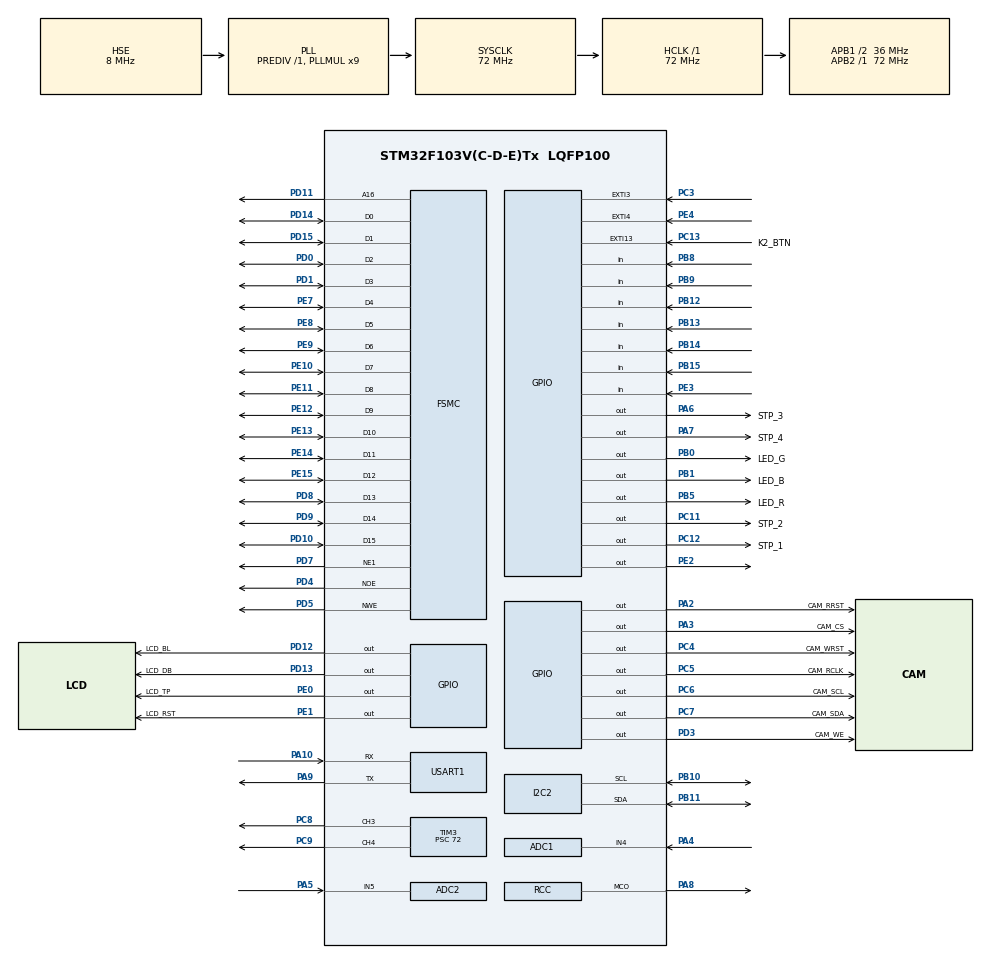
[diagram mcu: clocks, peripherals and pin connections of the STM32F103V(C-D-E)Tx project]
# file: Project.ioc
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ADC1.Channel-1\#ChannelRegularConversion=ADC_CHANNEL_4
ADC1.ContinuousConvMode=ENABLE
ADC1.NbrOfConversionFlag=1
ADC1.Rank-1\#ChannelRegularConversion=1
ADC1.SamplingTime-1\#ChannelRegularConversion=ADC_SAMPLETIME_1CYCLE_5
ADC1.master=1
ADC2.Channel-0\#ChannelRegularConversion=ADC_CHANNEL_5
ADC2.ContinuousConvMode=ENABLE
ADC2.NbrOfConversion=1
ADC2.NbrOfConversionFlag=1
ADC2.Rank-0\#ChannelRegularConversion=1
ADC2.SamplingTime-0\#ChannelRegularConversion=ADC_SAMPLETIME_1CYCLE_5
Mcu.Family=STM32F1
Mcu.Name=STM32F103V(C-D-E)Tx
Mcu.Package=LQFP100
NVIC.EXTI15_10_IRQn=true\:0\:0\:false\:false\:true\:true\:true\:true
NVIC.EXTI3_IRQn=true\:0\:0\:false\:false\:true\:true\:true\:true
NVIC.EXTI4_IRQn=true\:0\:0\:false\:false\:true\:true\:true\:true
NVIC.PriorityGroup=NVIC_PRIORITYGROUP_4
OSC_IN.Mode=HSE-External-Oscillator
OSC_IN.Signal=RCC_OSC_IN
OSC_OUT.Mode=HSE-External-Oscillator
OSC_OUT.Signal=RCC_OSC_OUT
PA10.Mode=Asynchronous
PA10.Signal=USART1_RX
PA13.Mode=Serial_Wire
PA13.Signal=SYS_JTMS-SWDIO
PA14.Mode=Serial_Wire
PA14.Signal=SYS_JTCK-SWCLK
PA2.GPIO_Label=CAM_RRST
PA2.GPIO_Speed=GPIO_SPEED_FREQ_HIGH
PA2.PinState=GPIO_PIN_RESET
PA2.Signal=GPIO_Output
PA3.GPIO_Label=CAM_CS
PA3.GPIO_Speed=GPIO_SPEED_FREQ_HIGH
PA3.Signal=GPIO_Output
PA4.Signal=ADCx_IN4
PA5.Signal=ADCx_IN5
PA6.GPIO_Label=STP_3
PA6.GPIO_Speed=GPIO_SPEED_FREQ_HIGH
PA6.PinState=GPIO_PIN_SET
PA6.Signal=GPIO_Output
PA7.GPIO_Label=STP_4
PA7.GPIO_Speed=GPIO_SPEED_FREQ_HIGH
PA7.PinState=GPIO_PIN_SET
PA7.Signal=GPIO_Output
PA8.Mode=Clock-out
PA8.Signal=RCC_MCO
PA9.Mode=Asynchronous
PA9.Signal=USART1_TX
PB0.GPIO_Label=LED_G
PB0.GPIO_Speed=GPIO_SPEED_FREQ_HIGH
PB0.PinState=GPIO_PIN_SET
PB0.Signal=GPIO_Output
PB1.GPIO_Label=LED_B
PB1.GPIO_Speed=GPIO_SPEED_FREQ_HIGH
PB1.PinState=GPIO_PIN_SET
PB1.Signal=GPIO_Output
PB10.Mode=I2C
PB10.Signal=I2C2_SCL
PB11.Mode=I2C
PB11.Signal=I2C2_SDA
PB12.Signal=GPIO_Input
PB13.Signal=GPIO_Input
PB14.Signal=GPIO_Input
PB15.Signal=GPIO_Input
PB5.GPIO_Label=LED_R
PB5.GPIO_Speed=GPIO_SPEED_FREQ_HIGH
PB5.PinState=GPIO_PIN_SET
PB5.Signal=GPIO_Output
PB8.Signal=GPIO_Input
PB9.Signal=GPIO_Input
PC11.GPIO_Label=STP_2
PC11.GPIO_Speed=GPIO_SPEED_FREQ_HIGH
PC11.PinState=GPIO_PIN_SET
PC11.Signal=GPIO_Output
PC12.GPIO_Label=STP_1
PC12.GPIO_Speed=GPIO_SPEED_FREQ_HIGH
PC12.PinState=GPIO_PIN_SET
PC12.Signal=GPIO_Output
PC13-TAMPER-RTC.GPIO_Label=K2_BTN
PC13-TAMPER-RTC.GPIO_ModeDefaultEXTI=GPIO_MODE_IT_RISING
PC13-TAMPER-RTC.Signal=GPXTI13
PC14-OSC32_IN.Mode=LSE-External-Oscillator
PC14-OSC32_IN.Signal=RCC_OSC32_IN
PC15-OSC32_OUT.Mode=LSE-External-Oscillator
PC15-OSC32_OUT.Signal=RCC_OSC32_OUT
PC3.GPIO_ModeDefaultEXTI=GPIO_MODE_IT_FALLING
PC3.Signal=GPXTI3
PC4.GPIO_Label=CAM_WRST
PC4.GPIO_Speed=GPIO_SPEED_FREQ_HIGH
PC4.Signal=GPIO_Output
PC5.GPIO_Label=CAM_RCLK
PC5.GPIO_Speed=GPIO_SPEED_FREQ_HIGH
PC5.Signal=GPIO_Output
PC6.GPIO_Label=CAM_SCL
PC6.GPIO_Speed=GPIO_SPEED_FREQ_HIGH
PC6.Signal=GPIO_Output
PC7.GPIO_Label=CAM_SDA
PC7.GPIO_ModeDefaultOutputPP=GPIO_MODE_OUTPUT_OD
PC7.GPIO_PuPd=GPIO_NOPULL
PC7.GPIO_Speed=GPIO_SPEED_FREQ_HIGH
PC7.Signal=GPIO_Output
PC8.GPIO_Speed=GPIO_SPEED_FREQ_HIGH
PC8.Signal=S_TIM3_CH3
PC9.GPIO_Speed=GPIO_SPEED_FREQ_HIGH
PC9.Signal=S_TIM3_CH4
PD0.Mode=16b-d1
PD0.Signal=FSMC_D2
PD1.Mode=16b-d1
PD1.Signal=FSMC_D3
PD10.Mode=16b-d1
PD10.Signal=FSMC_D15
PD11.Mode=A16_1
PD11.Signal=FSMC_A16
PD12.GPIO_Label=LCD_BL
PD12.GPIO_Speed=GPIO_SPEED_FREQ_HIGH
PD12.Signal=GPIO_Output
PD13.GPIO_Label=LCD_DB
PD13.GPIO_Speed=GPIO_SPEED_FREQ_HIGH
PD13.Signal=GPIO_Output
PD14.Mode=16b-d1
PD14.Signal=FSMC_D0
PD15.Mode=16b-d1
PD15.Signal=FSMC_D1
PD3.GPIO_Label=CAM_WE
PD3.GPIO_Speed=GPIO_SPEED_FREQ_HIGH
PD3.Signal=GPIO_Output
PD4.Mode=Lcd1
PD4.Signal=FSMC_NOE
PD5.Mode=Lcd1
PD5.Signal=FSMC_NWE
PD7.Mode=NorPsramChipSelect1_1
PD7.Signal=FSMC_NE1
PD8.Mode=16b-d1
PD8.Signal=FSMC_D13
PD9.Mode=16b-d1
PD9.Signal=FSMC_D14
PE0.GPIO_Label=LCD_TP
PE0.GPIO_Speed=GPIO_SPEED_FREQ_HIGH
PE0.Signal=GPIO_Output
PE1.GPIO_Label=LCD_RST
PE1.GPIO_Speed=GPIO_SPEED_FREQ_HIGH
PE1.Signal=GPIO_Output
PE10.Mode=16b-d1
PE10.Signal=FSMC_D7
PE11.Mode=16b-d1
PE11.Signal=FSMC_D8
PE12.Mode=16b-d1
PE12.Signal=FSMC_D9
PE13.Mode=16b-d1
PE13.Signal=FSMC_D10
PE14.Mode=16b-d1
PE14.Signal=FSMC_D11
PE15.Mode=16b-d1
PE15.Signal=FSMC_D12
PE2.GPIO_Speed=GPIO_SPEED_FREQ_HIGH
PE2.Signal=GPIO_Output
PE3.GPIO_PuPd=GPIO_PULLUP
PE3.Signal=GPIO_Input
PE4.GPIO_ModeDefaultEXTI=GPIO_MODE_IT_FALLING
PE4.Signal=GPXTI4
PE7.Mode=16b-d1
PE7.Signal=FSMC_D4
PE8.Mode=16b-d1
PE8.Signal=FSMC_D5
PE9.Mode=16b-d1
PE9.Signal=FSMC_D6
ProjectManager.HeapSize=0x200
ProjectManager.StackSize=0x400
ProjectManager.TargetToolchain=STM32CubeIDE
RCC.ADCPresc=RCC_ADCPCLK2_DIV6
RCC.AHBFreq_Value=72000000
RCC.APB1CLKDivider=RCC_HCLK_DIV2
RCC.APB1Freq_Value=36000000
RCC.APB1TimFreq_Value=72000000
RCC.APB2Freq_Value=72000000
RCC.APB2TimFreq_Value=72000000
RCC.HCLKFreq_Value=72000000
RCC.PLLMUL=RCC_PLL_MUL9
RCC.PLLSourceVirtual=RCC_PLLSOURCE_HSE
RCC.RCC_MCOSource=RCC_MCO1SOURCE_PLLCLK
RCC.SYSCLKFreq_VALUE=72000000
RCC.SYSCLKSource=RCC_SYSCLKSOURCE_PLLCLK
RCC.USBFreq_Value=72000000
SH.ADCx_IN4.0=ADC1_IN4,IN4
SH.ADCx_IN5.0=ADC2_IN5,IN5
SH.S_TIM3_CH3.0=TIM3_CH3,PWM Generation3 CH3
SH.S_TIM3_CH4.0=TIM3_CH4,PWM Generation4 CH4
TIM1.Period=0xffff-1
TIM1.Prescaler=72-1
TIM3.Channel-PWM\ Generation3\ CH3=TIM_CHANNEL_3
TIM3.Channel-PWM\ Generation4\ CH4=TIM_CHANNEL_4
TIM3.Period=20000-1
TIM3.Prescaler=72
TIM3.Pulse-PWM\ Generation3\ CH3=2000
TIM3.Pulse-PWM\ Generation4\ CH4=2000
USART1.VirtualMode=VM_ASYNC
VP_TIM1_VS_ClockSourceINT.Mode=Internal
board=custom

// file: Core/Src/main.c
/* USER CODE BEGIN Header */
/**
 ******************************************************************************
 * @file           : main.c
 * @brief          : Main program body
 ******************************************************************************
 * @attention
 *
 * Copyright (c) 2024 STMicroelectronics.
 * All rights reserved.
 *
 * This software is licensed under terms that can be found in the LICENSE file
 * in the root directory of this software component.
 * If no LICENSE file comes with this software, it is provided AS-IS.
 *
 ******************************************************************************
 */
/* USER CODE END Header */
#include "main.h"

 ADC_HandleTypeDef hadc1;
ADC_HandleTypeDef hadc2;

I2C_HandleTypeDef hi2c2;

TIM_HandleTypeDef htim1;
TIM_HandleTypeDef htim3;

UART_HandleTypeDef huart1;

SRAM_HandleTypeDef hsram1;

/* USER CODE BEGIN PV */
volatile uint8_t isScreenTouched = 0;
/* USER CODE END PV */

void SystemClock_Config(void);
static void MX_GPIO_Init(void);
static void MX_FSMC_Init(void);
static void MX_I2C2_Init(void);
static void MX_USART1_UART_Init(void);
static void MX_TIM1_Init(void);
static void MX_TIM3_Init(void);
static void MX_ADC1_Init(void);
static void MX_ADC2_Init(void);

int main(void)
{

  /* MCU Configuration--------------------------------------------------------*/

  /* Reset of all peripherals, Initializes the Flash interface and the Systick. */
  HAL_Init();

  /* Configure the system clock */
  SystemClock_Config();

  /* Initialize all configured peripherals */
  MX_GPIO_Init();
  MX_FSMC_Init();
  MX_I2C2_Init();
  MX_USART1_UART_Init();
  MX_TIM1_Init();
  MX_TIM3_Init();
  MX_ADC1_Init();
  MX_ADC2_Init();

  /* Infinite loop */
  /* USER CODE BEGIN WHILE */

  // this is the entry point to my C++ source code files.
  // the STM32CubeIDE does not seem to be able to generate and update
  // C++ main.cpp files for some reason.
  // the work around is to have another C++ source file that contains the
  // real entry point which this generated main.c source file will call after
  // completing initialization.
  extern int mymain(void);

  //  while (1)  comment out the while() because the main loop is in mymain() in mymain.cpp

  // this is the entry point to my C++ source code files.
  // the STM32CubeIDE does not seem to be able to generate and update
  // C++ main.cpp files for some reason.
  // the work around is to have another C++ source file that contains the
  // real entry point which this generated main.c source file will call after
  // completing initialization.
  extern int mymain(void);

  //  while (1)  comment out the while() because the main loop is in mymain() in mymain.cpp
  {
    /* USER CODE END WHILE */

    /* USER CODE BEGIN 3 */
  }

  // the main entry point in the C++ source after initializing
  // the runtime environment.
  return mymain();

  // the main entry point in the C++ source after initializing
  // the runtime environment.
  return mymain();
  /* USER CODE END 3 */
}

void SystemClock_Config(void)
{
  RCC_OscInitTypeDef RCC_OscInitStruct = {0};
  RCC_ClkInitTypeDef RCC_ClkInitStruct = {0};
  RCC_PeriphCLKInitTypeDef PeriphClkInit = {0};

  /** Initializes the RCC Oscillators according to the specified parameters
  * in the RCC_OscInitTypeDef structure.
  */
  RCC_OscInitStruct.OscillatorType = RCC_OSCILLATORTYPE_HSE;
  RCC_OscInitStruct.HSEState = RCC_HSE_ON;
  RCC_OscInitStruct.HSEPredivValue = RCC_HSE_PREDIV_DIV1;
  RCC_OscInitStruct.HSIState = RCC_HSI_ON;
  RCC_OscInitStruct.PLL.PLLState = RCC_PLL_ON;
  RCC_OscInitStruct.PLL.PLLSource = RCC_PLLSOURCE_HSE;
  RCC_OscInitStruct.PLL.PLLMUL = RCC_PLL_MUL9;
  if (HAL_RCC_OscConfig(&RCC_OscInitStruct) != HAL_OK)
  {
    Error_Handler();
  }

  /** Initializes the CPU, AHB and APB buses clocks
  */
  RCC_ClkInitStruct.ClockType = RCC_CLOCKTYPE_HCLK|RCC_CLOCKTYPE_SYSCLK
                              |RCC_CLOCKTYPE_PCLK1|RCC_CLOCKTYPE_PCLK2;
  RCC_ClkInitStruct.SYSCLKSource = RCC_SYSCLKSOURCE_PLLCLK;
  RCC_ClkInitStruct.AHBCLKDivider = RCC_SYSCLK_DIV1;
  RCC_ClkInitStruct.APB1CLKDivider = RCC_HCLK_DIV2;
  RCC_ClkInitStruct.APB2CLKDivider = RCC_HCLK_DIV1;

  if (HAL_RCC_ClockConfig(&RCC_ClkInitStruct, FLASH_LATENCY_2) != HAL_OK)
  {
    Error_Handler();
  }
  PeriphClkInit.PeriphClockSelection = RCC_PERIPHCLK_ADC;
  PeriphClkInit.AdcClockSelection = RCC_ADCPCLK2_DIV6;
  if (HAL_RCCEx_PeriphCLKConfig(&PeriphClkInit) != HAL_OK)
  {
    Error_Handler();
  }
  HAL_RCC_MCOConfig(RCC_MCO, RCC_MCO1SOURCE_PLLCLK, RCC_MCODIV_1);
}

static void MX_ADC1_Init(void)
{

  ADC_ChannelConfTypeDef sConfig = {0};

  /** Common config
  */
  hadc1.Instance = ADC1;
  hadc1.Init.ScanConvMode = ADC_SCAN_DISABLE;
  hadc1.Init.ContinuousConvMode = ENABLE;
  hadc1.Init.DiscontinuousConvMode = DISABLE;
  hadc1.Init.ExternalTrigConv = ADC_SOFTWARE_START;
  hadc1.Init.DataAlign = ADC_DATAALIGN_RIGHT;
  hadc1.Init.NbrOfConversion = 1;
  if (HAL_ADC_Init(&hadc1) != HAL_OK)
  {
    Error_Handler();
  }

  /** Configure Regular Channel
  */
  sConfig.Channel = ADC_CHANNEL_4;
  sConfig.Rank = ADC_REGULAR_RANK_1;
  sConfig.SamplingTime = ADC_SAMPLETIME_1CYCLE_5;
  if (HAL_ADC_ConfigChannel(&hadc1, &sConfig) != HAL_OK)
  {
    Error_Handler();
  }

}

static void MX_ADC2_Init(void)
{

  ADC_ChannelConfTypeDef sConfig = {0};

  /** Common config
  */
  hadc2.Instance = ADC2;
  hadc2.Init.ScanConvMode = ADC_SCAN_DISABLE;
  hadc2.Init.ContinuousConvMode = ENABLE;
  hadc2.Init.DiscontinuousConvMode = DISABLE;
  hadc2.Init.ExternalTrigConv = ADC_SOFTWARE_START;
  hadc2.Init.DataAlign = ADC_DATAALIGN_RIGHT;
  hadc2.Init.NbrOfConversion = 1;
  if (HAL_ADC_Init(&hadc2) != HAL_OK)
  {
    Error_Handler();
  }

  /** Configure Regular Channel
  */
  sConfig.Channel = ADC_CHANNEL_5;
  sConfig.Rank = ADC_REGULAR_RANK_1;
  sConfig.SamplingTime = ADC_SAMPLETIME_1CYCLE_5;
  if (HAL_ADC_ConfigChannel(&hadc2, &sConfig) != HAL_OK)
  {
    Error_Handler();
  }

}

static void MX_I2C2_Init(void)
{

  hi2c2.Instance = I2C2;
  hi2c2.Init.ClockSpeed = 100000;
  hi2c2.Init.DutyCycle = I2C_DUTYCYCLE_2;
  hi2c2.Init.OwnAddress1 = 0;
  hi2c2.Init.AddressingMode = I2C_ADDRESSINGMODE_7BIT;
  hi2c2.Init.DualAddressMode = I2C_DUALADDRESS_DISABLE;
  hi2c2.Init.OwnAddress2 = 0;
  hi2c2.Init.GeneralCallMode = I2C_GENERALCALL_DISABLE;
  hi2c2.Init.NoStretchMode = I2C_NOSTRETCH_DISABLE;
  if (HAL_I2C_Init(&hi2c2) != HAL_OK)
  {
    Error_Handler();
  }

}

static void MX_TIM1_Init(void)
{

  TIM_ClockConfigTypeDef sClockSourceConfig = {0};
  TIM_MasterConfigTypeDef sMasterConfig = {0};

  htim1.Instance = TIM1;
  htim1.Init.Prescaler = 72-1;
  htim1.Init.CounterMode = TIM_COUNTERMODE_UP;
  htim1.Init.Period = 0xffff-1;
  htim1.Init.ClockDivision = TIM_CLOCKDIVISION_DIV1;
  htim1.Init.RepetitionCounter = 0;
  htim1.Init.AutoReloadPreload = TIM_AUTORELOAD_PRELOAD_DISABLE;
  if (HAL_TIM_Base_Init(&htim1) != HAL_OK)
  {
    Error_Handler();
  }
  sClockSourceConfig.ClockSource = TIM_CLOCKSOURCE_INTERNAL;
  if (HAL_TIM_ConfigClockSource(&htim1, &sClockSourceConfig) != HAL_OK)
  {
    Error_Handler();
  }
  sMasterConfig.MasterOutputTrigger = TIM_TRGO_RESET;
  sMasterConfig.MasterSlaveMode = TIM_MASTERSLAVEMODE_DISABLE;
  if (HAL_TIMEx_MasterConfigSynchronization(&htim1, &sMasterConfig) != HAL_OK)
  {
    Error_Handler();
  }

}

static void MX_TIM3_Init(void)
{

  TIM_MasterConfigTypeDef sMasterConfig = {0};
  TIM_OC_InitTypeDef sConfigOC = {0};

  htim3.Instance = TIM3;
  htim3.Init.Prescaler = 72;
  htim3.Init.CounterMode = TIM_COUNTERMODE_UP;
  htim3.Init.Period = 20000-1;
  htim3.Init.ClockDivision = TIM_CLOCKDIVISION_DIV1;
  htim3.Init.AutoReloadPreload = TIM_AUTORELOAD_PRELOAD_DISABLE;
  if (HAL_TIM_PWM_Init(&htim3) != HAL_OK)
  {
    Error_Handler();
  }
  sMasterConfig.MasterOutputTrigger = TIM_TRGO_RESET;
  sMasterConfig.MasterSlaveMode = TIM_MASTERSLAVEMODE_DISABLE;
  if (HAL_TIMEx_MasterConfigSynchronization(&htim3, &sMasterConfig) != HAL_OK)
  {
    Error_Handler();
  }
  sConfigOC.OCMode = TIM_OCMODE_PWM1;
  sConfigOC.Pulse = 2000;
  sConfigOC.OCPolarity = TIM_OCPOLARITY_HIGH;
  sConfigOC.OCFastMode = TIM_OCFAST_DISABLE;
  if (HAL_TIM_PWM_ConfigChannel(&htim3, &sConfigOC, TIM_CHANNEL_3) != HAL_OK)
  {
    Error_Handler();
  }
  if (HAL_TIM_PWM_ConfigChannel(&htim3, &sConfigOC, TIM_CHANNEL_4) != HAL_OK)
  {
    Error_Handler();
  }
  HAL_TIM_MspPostInit(&htim3);

}

static void MX_USART1_UART_Init(void)
{

  huart1.Instance = USART1;
  huart1.Init.BaudRate = 115200;
  huart1.Init.WordLength = UART_WORDLENGTH_8B;
  huart1.Init.StopBits = UART_STOPBITS_1;
  huart1.Init.Parity = UART_PARITY_NONE;
  huart1.Init.Mode = UART_MODE_TX_RX;
  huart1.Init.HwFlowCtl = UART_HWCONTROL_NONE;
  huart1.Init.OverSampling = UART_OVERSAMPLING_16;
  if (HAL_UART_Init(&huart1) != HAL_OK)
  {
    Error_Handler();
  }

}

static void MX_GPIO_Init(void)
{
  GPIO_InitTypeDef GPIO_InitStruct = {0};

  /* GPIO Ports Clock Enable */
  __HAL_RCC_GPIOE_CLK_ENABLE();
  __HAL_RCC_GPIOC_CLK_ENABLE();
  __HAL_RCC_GPIOA_CLK_ENABLE();
  __HAL_RCC_GPIOB_CLK_ENABLE();
  __HAL_RCC_GPIOD_CLK_ENABLE();

  /*Configure GPIO pin Output Level */
  HAL_GPIO_WritePin(GPIOE, GPIO_PIN_2|LCD_TP_Pin|LCD_RST_Pin, GPIO_PIN_RESET);

  /*Configure GPIO pin Output Level */
  HAL_GPIO_WritePin(GPIOA, CAM_RRST_Pin|CAM_CS_Pin, GPIO_PIN_RESET);

  /*Configure GPIO pin Output Level */
  HAL_GPIO_WritePin(GPIOA, STP_3_Pin|STP_4_Pin, GPIO_PIN_SET);

  /*Configure GPIO pin Output Level */
  HAL_GPIO_WritePin(GPIOC, CAM_WRST_Pin|CAM_RCLK_Pin|CAM_SCL_Pin|CAM_SDA_Pin, GPIO_PIN_RESET);

  /*Configure GPIO pin Output Level */
  HAL_GPIO_WritePin(GPIOB, LED_G_Pin|LED_B_Pin|LED_R_Pin, GPIO_PIN_SET);

  /*Configure GPIO pin Output Level */
  HAL_GPIO_WritePin(GPIOD, LCD_BL_Pin|LCD_DB_Pin|CAM_WE_Pin, GPIO_PIN_RESET);

  /*Configure GPIO pin Output Level */
  HAL_GPIO_WritePin(GPIOC, STP_2_Pin|STP_1_Pin, GPIO_PIN_SET);

  /*Configure GPIO pins : PE2 LCD_TP_Pin LCD_RST_Pin */
  GPIO_InitStruct.Pin = GPIO_PIN_2|LCD_TP_Pin|LCD_RST_Pin;
  GPIO_InitStruct.Mode = GPIO_MODE_OUTPUT_PP;
  GPIO_InitStruct.Pull = GPIO_NOPULL;
  GPIO_InitStruct.Speed = GPIO_SPEED_FREQ_HIGH;
  HAL_GPIO_Init(GPIOE, &GPIO_InitStruct);

  /*Configure GPIO pin : PE3 */
  GPIO_InitStruct.Pin = GPIO_PIN_3;
  GPIO_InitStruct.Mode = GPIO_MODE_INPUT;
  GPIO_InitStruct.Pull = GPIO_PULLUP;
  HAL_GPIO_Init(GPIOE, &GPIO_InitStruct);

  /*Configure GPIO pin : PE4 */
  GPIO_InitStruct.Pin = GPIO_PIN_4;
  GPIO_InitStruct.Mode = GPIO_MODE_IT_FALLING;
  GPIO_InitStruct.Pull = GPIO_NOPULL;
  HAL_GPIO_Init(GPIOE, &GPIO_InitStruct);

  /*Configure GPIO pin : K2_BTN_Pin */
  GPIO_InitStruct.Pin = K2_BTN_Pin;
  GPIO_InitStruct.Mode = GPIO_MODE_IT_RISING;
  GPIO_InitStruct.Pull = GPIO_NOPULL;
  HAL_GPIO_Init(K2_BTN_GPIO_Port, &GPIO_InitStruct);

  /*Configure GPIO pin : PC3 */
  GPIO_InitStruct.Pin = GPIO_PIN_3;
  GPIO_InitStruct.Mode = GPIO_MODE_IT_FALLING;
  GPIO_InitStruct.Pull = GPIO_NOPULL;
  HAL_GPIO_Init(GPIOC, &GPIO_InitStruct);

  /*Configure GPIO pins : CAM_RRST_Pin CAM_CS_Pin STP_3_Pin STP_4_Pin */
  GPIO_InitStruct.Pin = CAM_RRST_Pin|CAM_CS_Pin|STP_3_Pin|STP_4_Pin;
  GPIO_InitStruct.Mode = GPIO_MODE_OUTPUT_PP;
  GPIO_InitStruct.Pull = GPIO_NOPULL;
  GPIO_InitStruct.Speed = GPIO_SPEED_FREQ_HIGH;
  HAL_GPIO_Init(GPIOA, &GPIO_InitStruct);

  /*Configure GPIO pins : CAM_WRST_Pin CAM_RCLK_Pin CAM_SCL_Pin STP_2_Pin
                           STP_1_Pin */
  GPIO_InitStruct.Pin = CAM_WRST_Pin|CAM_RCLK_Pin|CAM_SCL_Pin|STP_2_Pin
                          |STP_1_Pin;
  GPIO_InitStruct.Mode = GPIO_MODE_OUTPUT_PP;
  GPIO_InitStruct.Pull = GPIO_NOPULL;
  GPIO_InitStruct.Speed = GPIO_SPEED_FREQ_HIGH;
  HAL_GPIO_Init(GPIOC, &GPIO_InitStruct);

  /*Configure GPIO pins : LED_G_Pin LED_B_Pin LED_R_Pin */
  GPIO_InitStruct.Pin = LED_G_Pin|LED_B_Pin|LED_R_Pin;
  GPIO_InitStruct.Mode = GPIO_MODE_OUTPUT_PP;
  GPIO_InitStruct.Pull = GPIO_NOPULL;
  GPIO_InitStruct.Speed = GPIO_SPEED_FREQ_HIGH;
  HAL_GPIO_Init(GPIOB, &GPIO_InitStruct);

  /*Configure GPIO pins : PB12 PB13 PB14 PB15
                           PB8 PB9 */
  GPIO_InitStruct.Pin = GPIO_PIN_12|GPIO_PIN_13|GPIO_PIN_14|GPIO_PIN_15
                          |GPIO_PIN_8|GPIO_PIN_9;
  GPIO_InitStruct.Mode = GPIO_MODE_INPUT;
  GPIO_InitStruct.Pull = GPIO_NOPULL;
  HAL_GPIO_Init(GPIOB, &GPIO_InitStruct);

  /*Configure GPIO pins : LCD_BL_Pin LCD_DB_Pin CAM_WE_Pin */
  GPIO_InitStruct.Pin = LCD_BL_Pin|LCD_DB_Pin|CAM_WE_Pin;
  GPIO_InitStruct.Mode = GPIO_MODE_OUTPUT_PP;
  GPIO_InitStruct.Pull = GPIO_NOPULL;
  GPIO_InitStruct.Speed = GPIO_SPEED_FREQ_HIGH;
  HAL_GPIO_Init(GPIOD, &GPIO_InitStruct);

  /*Configure GPIO pin : CAM_SDA_Pin */
  GPIO_InitStruct.Pin = CAM_SDA_Pin;
  GPIO_InitStruct.Mode = GPIO_MODE_OUTPUT_OD;
  GPIO_InitStruct.Pull = GPIO_NOPULL;
  GPIO_InitStruct.Speed = GPIO_SPEED_FREQ_HIGH;
  HAL_GPIO_Init(CAM_SDA_GPIO_Port, &GPIO_InitStruct);

  /*Configure GPIO pin : PA8 */
  GPIO_InitStruct.Pin = GPIO_PIN_8;
  GPIO_InitStruct.Mode = GPIO_MODE_AF_PP;
  GPIO_InitStruct.Speed = GPIO_SPEED_FREQ_LOW;
  HAL_GPIO_Init(GPIOA, &GPIO_InitStruct);

  /* EXTI interrupt init*/
  HAL_NVIC_SetPriority(EXTI3_IRQn, 0, 0);
  HAL_NVIC_EnableIRQ(EXTI3_IRQn);

  HAL_NVIC_SetPriority(EXTI4_IRQn, 0, 0);
  HAL_NVIC_EnableIRQ(EXTI4_IRQn);

  HAL_NVIC_SetPriority(EXTI15_10_IRQn, 0, 0);
  HAL_NVIC_EnableIRQ(EXTI15_10_IRQn);

}

/* FSMC initialization function */
static void MX_FSMC_Init(void)
{

  FSMC_NORSRAM_TimingTypeDef Timing = {0};

  /** Perform the SRAM1 memory initialization sequence
  */
  hsram1.Instance = FSMC_NORSRAM_DEVICE;
  hsram1.Extended = FSMC_NORSRAM_EXTENDED_DEVICE;
  /* hsram1.Init */
  hsram1.Init.NSBank = FSMC_NORSRAM_BANK1;
  hsram1.Init.DataAddressMux = FSMC_DATA_ADDRESS_MUX_DISABLE;
  hsram1.Init.MemoryType = FSMC_MEMORY_TYPE_SRAM;
  hsram1.Init.MemoryDataWidth = FSMC_NORSRAM_MEM_BUS_WIDTH_16;
  hsram1.Init.BurstAccessMode = FSMC_BURST_ACCESS_MODE_DISABLE;
  hsram1.Init.WaitSignalPolarity = FSMC_WAIT_SIGNAL_POLARITY_LOW;
  hsram1.Init.WrapMode = FSMC_WRAP_MODE_DISABLE;
  hsram1.Init.WaitSignalActive = FSMC_WAIT_TIMING_BEFORE_WS;
  hsram1.Init.WriteOperation = FSMC_WRITE_OPERATION_ENABLE;
  hsram1.Init.WaitSignal = FSMC_WAIT_SIGNAL_DISABLE;
  hsram1.Init.ExtendedMode = FSMC_EXTENDED_MODE_DISABLE;
  hsram1.Init.AsynchronousWait = FSMC_ASYNCHRONOUS_WAIT_DISABLE;
  hsram1.Init.WriteBurst = FSMC_WRITE_BURST_DISABLE;
  /* Timing */
  Timing.AddressSetupTime = 15;
  Timing.AddressHoldTime = 15;
  Timing.DataSetupTime = 255;
  Timing.BusTurnAroundDuration = 15;
  Timing.CLKDivision = 16;
  Timing.DataLatency = 17;
  Timing.AccessMode = FSMC_ACCESS_MODE_A;
  /* ExtTiming */

  if (HAL_SRAM_Init(&hsram1, &Timing, NULL) != HAL_OK)
  {
    Error_Handler( );
  }

  /** Disconnect NADV
  */

  __HAL_AFIO_FSMCNADV_DISCONNECTED();

}

void Error_Handler(void)
{
  __disable_irq();
  while (1)
  {
  }
}
